# MSP432P411V register map
Vendor: Texas Instruments; File version: 3.230
CPU: 
Registers are 32-bit, read-write, reset 0x0 unless marked. A register's access mark holds for its fields unless they carry their own. Offsets are from the block's base; [hi:lo] are bit positions; {n}, {i} and the like mark numbered series; 'fields as' and 'values as' point back to an identical list.

## FLCTL_A
Base 0x40011000
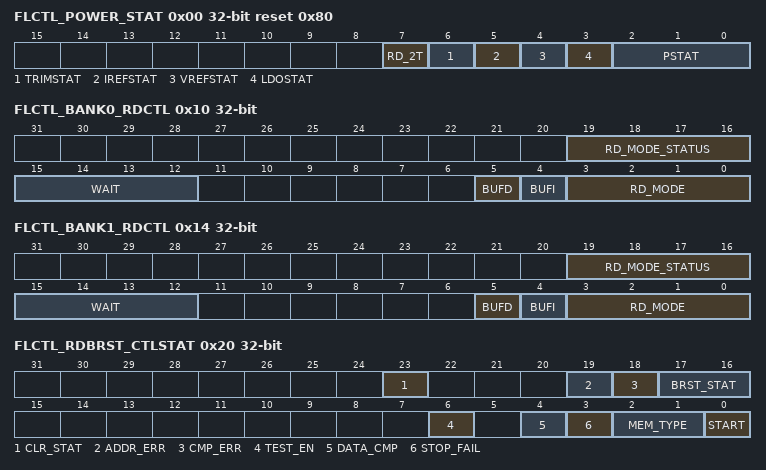
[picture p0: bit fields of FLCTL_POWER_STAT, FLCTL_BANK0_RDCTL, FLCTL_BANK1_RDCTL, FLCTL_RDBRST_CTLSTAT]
0x00 FLCTL_POWER_STAT ro reset 0x80 — Power Status Register
  [7] RD_2T — Indicates if Flash is being accessed in 2T mode
    0=Flash reads are in 1T mode; 1=Flash reads are in 2T mode
  [6] TRIMSTAT — PSS trim done status
    0=PSS trim not complete; 1=PSS trim complete
  [5] IREFSTAT — PSS IREF stable status
    0=IREF not stable; 1=IREF stable
  [4] VREFSTAT — PSS VREF stable status
    0=Flash LDO not stable; 1=Flash LDO stable
  [3] LDOSTAT — PSS FLDO GOOD status
    0=FLDO not GOOD; 1=FLDO GOOD
  [2:0] PSTAT — Flash power status
    0=Flash IP in power-down mode; 1=Flash IP Vdd domain power-up in progress; 2=PSS LDO_GOOD, IREF_OK and VREF_OK check in progress; 3=Flash IP SAFE_LV check in progress; 4=Flash IP Active; 5=Flash IP Active in Low-Frequency Active and Low-Frequency LPM0 modes; 6=Flash IP in Standby mode; 7=Flash IP in Current mirror boost state
0x10 FLCTL_BANK0_RDCTL access per field — Bank0 Read Control Register
  [19:16] RD_MODE_STATUS ro — Read mode
    0=Normal read mode; 1=Read Margin 0; 2=Read Margin 1; 3=Program Verify; 4=Erase Verify; 5=Leakage Verify; 9=Read Margin 0B; 10=Read Margin 1B
  [15:12] WAIT rw — Number of wait states for read
    {v}={v} wait states (v=0..15)
  [5] BUFD rw — Enables read buffering feature for data reads to this Bank
  [4] BUFI rw — Enables read buffering feature for instruction fetches to this Bank
  [3:0] RD_MODE rw — Flash read mode control setting for Bank 0
    values as RD_MODE_STATUS
0x14 FLCTL_BANK1_RDCTL access per field — Bank1 Read Control Register
  fields as FLCTL_BANK0_RDCTL
0x20 FLCTL_RDBRST_CTLSTAT access per field — Read Burst/Compare Control and Status Register
  [23] CLR_STAT wo — Clear status bits 19-16 of this register
  [19] ADDR_ERR ro — Burst/Compare Operation was terminated due to access to
  [18] CMP_ERR ro — Burst/Compare Operation encountered atleast one data
  [17:16] BRST_STAT ro — Status of Burst/Compare operation
    0=Idle; 1=Burst/Compare START bit written, but operation pending; 2=Burst/Compare in progress; 3=Burst complete (status of completed burst remains in this state unless explicitly cleared by SW)
  [6] TEST_EN rw — Enable comparison against test data compare registers
  [4] DATA_CMP rw — Data pattern used for comparison against memory read data
    0=0000_0000_0000_0000_0000_0000_0000_0000; 1=FFFF_FFFF_FFFF_FFFF_FFFF_FFFF_FFFF_FFFF
  [3] STOP_FAIL rw — Terminate burst/compare operation
  [2:1] MEM_TYPE rw — Type of memory that burst is carried out on
    0=Main Memory; 1=Information Memory; 3=Engineering Memory
  [0] START wo — Start of burst/compare operation
0x24 FLCTL_RDBRST_STARTADDR — Read Burst/Compare Start Address Register
  [20:0] START_ADDRESS — Start Address of Burst Operation
0x28 FLCTL_RDBRST_LEN — Read Burst/Compare Length Register
  [20:0] BURST_LENGTH — Length of Burst Operation
0x3C FLCTL_RDBRST_FAILADDR — Read Burst/Compare Fail Address Register
  [20:0] FAIL_ADDRESS — Reflects address of last failed compare
0x40 FLCTL_RDBRST_FAILCNT — Read Burst/Compare Fail Count Register
  [16:0] FAIL_COUNT — Number of failures encountered in burst operation
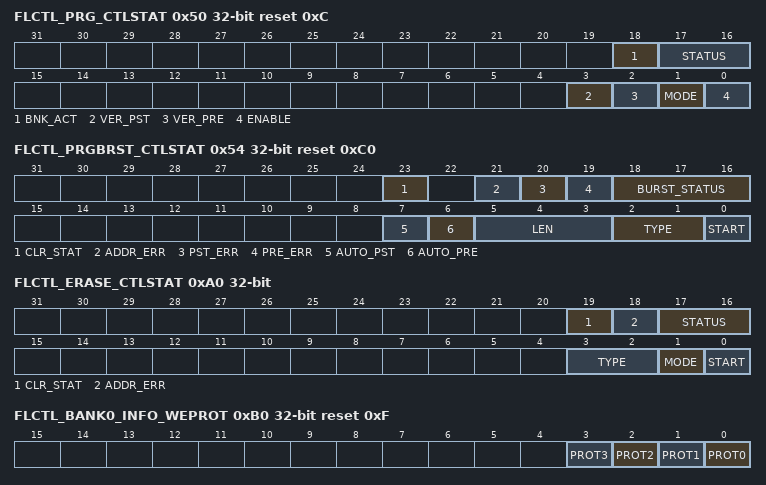
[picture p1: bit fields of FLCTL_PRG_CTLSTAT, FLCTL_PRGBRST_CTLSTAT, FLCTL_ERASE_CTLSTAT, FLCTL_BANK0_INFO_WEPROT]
0x50 FLCTL_PRG_CTLSTAT access per field reset 0xC — Program Control and Status Register
  [18] BNK_ACT ro — Bank active
    0=Word in Bank0 being programmed; 1=Word in Bank1 being programmed
  [17:16] STATUS ro — Status of program operations in the Flash memory
    0=Idle (no program operation currently active); 1=Single word program operation triggered, but pending; 2=Single word program in progress
  [3] VER_PST rw — Controls automatic post program verify operations
    0=No post program verification; 1=Post verify feature automatically invoked for each write operation (irrespective of the mode)
  [2] VER_PRE rw — Controls automatic pre program verify operations
    0=No pre program verification; 1=Pre verify feature automatically invoked for each write operation (irrespective of the mode)
  [1] MODE rw — Write mode
    0=Write immediate mode. Starts program operation immediately on each write to the Flash; 1=Full word write mode. Flash controller collates data over multiple writes to compose the full 128bit word before initiating the program operation
  [0] ENABLE rw — Master control for all word program operations
    0=Word program operation disabled; 1=Word program operation enabled
0x54 FLCTL_PRGBRST_CTLSTAT access per field reset 0xC0 — Program Burst Control and Status Register
  [23] CLR_STAT wo — Clear status bits 21-16 of this register
  [21] ADDR_ERR ro — Burst Operation was terminated due to attempted program of reserved memory
  [20] PST_ERR ro — Burst Operation encountered postprogram auto-verify errors
  [19] PRE_ERR ro — Burst Operation encountered preprogram auto-verify errors
  [18:16] BURST_STATUS ro — Status of a Burst Operation
    0=Idle (Burst not active); 1=Burst program started but pending; 2=Burst active, with 1st 128 bit word being written into Flash; 3=Burst active, with 2nd 128 bit word being written into Flash; 4=Burst active, with 3rd 128 bit word being written into Flash; 5=Burst active, with 4th 128 bit word being written into Flash; 7=Burst Complete (status of completed burst remains in this state unless explicitly cleared by SW)
  [7] AUTO_PST rw — Auto-Verify operation after the Burst Program
    0=No program verify operations carried out; 1=Causes an automatic Burst Program Verify before the Burst Program Operation
  [6] AUTO_PRE rw — Auto-Verify operation before the Burst Program
    0=No program verify operations carried out; 1=Causes an automatic Burst Program Verify after the Burst Program Operation
  [5:3] LEN rw — Length of burst
    0=No burst operation; 1=1 word burst of 128 bits, starting with address in the FLCTL_PRGBRST_STARTADDR Register; 2=2*128 bits burst write, starting with address in the FLCTL_PRGBRST_STARTADDR Register; 3=3*128 bits burst write, starting with address in the FLCTL_PRGBRST_STARTADDR Register; 4=4*128 bits burst write, starting with address in the FLCTL_PRGBRST_STARTADDR Register
  [2:1] TYPE rw — Type of memory that burst program is carried out on
    0=Main Memory; 1=Information Memory; 3=Engineering Memory
  [0] START wo — Trigger start of burst program operation
0x58 FLCTL_PRGBRST_STARTADDR — Program Burst Start Address Register
  [21:0] START_ADDRESS — Start Address of Program Burst Operation
{0x60+0x10*i} FLCTL_PRGBRST_DATA{i}_0 reset 0xFFFFFFFF (i=0..3) — Program Burst Data{i} Register0
  [31:0] DATAIN — Program Burst 128 bit Data Word {i}
{0x64+0x10*i} FLCTL_PRGBRST_DATA{i}_1 reset 0xFFFFFFFF (i=0..3) — Program Burst Data{i} Register1
  [31:0] DATAIN — Program Burst 128 bit Data Word {i}
{0x68+0x10*i} FLCTL_PRGBRST_DATA{i}_2 reset 0xFFFFFFFF (i=0..3) — Program Burst Data{i} Register2
  [31:0] DATAIN — Program Burst 128 bit Data Word {i}
{0x6C+0x10*i} FLCTL_PRGBRST_DATA{i}_3 reset 0xFFFFFFFF (i=0..3) — Program Burst Data{i} Register3
  [31:0] DATAIN — Program Burst 128 bit Data Word {i}
0xA0 FLCTL_ERASE_CTLSTAT access per field — Erase Control and Status Register
  [19] CLR_STAT wo — Clear status bits 18-16 of this register
  [18] ADDR_ERR ro — Erase Operation was terminated due to attempted erase of reserved memory address
  [17:16] STATUS ro — Status of erase operations in the Flash memory
    0=Idle (no program operation currently active); 1=Erase operation triggered to START but pending; 2=Erase operation in progress; 3=Erase operation completed (status of completed erase remains in this state unless explicitly cleared by SW)
  [3:2] TYPE rw — Type of memory that erase operation is carried out on
    0=Main Memory; 1=Information Memory; 3=Engineering Memory
  [1] MODE rw — Erase mode selected by application
    0=Sector Erase (controlled by FLTCTL_ERASE_SECTADDR); 1=Mass Erase (includes all Main and Information memory sectors that don't have corresponding WE bits set)
  [0] START wo — Start of Erase operation
0xA4 FLCTL_ERASE_SECTADDR — Erase Sector Address Register
  [21:0] SECT_ADDRESS — Address of Sector being Erased
0xB0 FLCTL_BANK0_INFO_WEPROT reset 0xF — Information Memory Bank0 Write/Erase Protection Register
  [n] PROT{n} (n=0..3) — Protects Sector {n} from program or erase
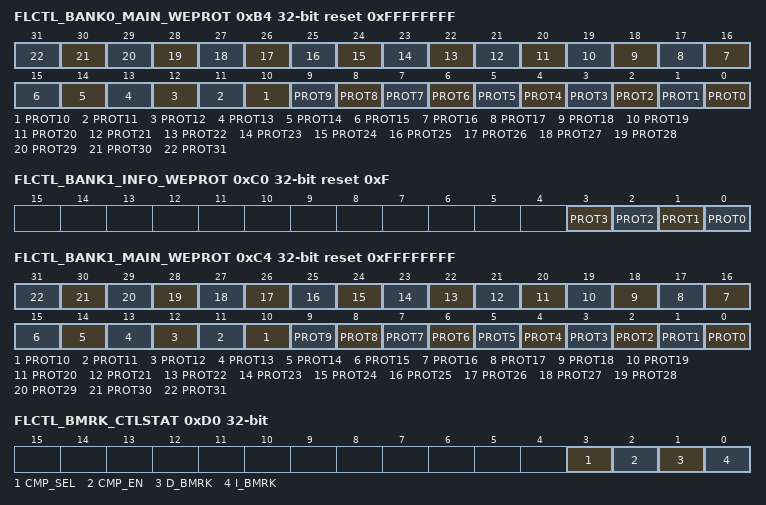
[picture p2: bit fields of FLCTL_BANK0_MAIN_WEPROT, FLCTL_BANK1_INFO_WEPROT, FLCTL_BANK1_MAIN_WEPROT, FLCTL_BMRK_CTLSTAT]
0xB4 FLCTL_BANK0_MAIN_WEPROT reset 0xFFFFFFFF — Main Memory Bank0 Write/Erase Protection Register
  [n] PROT{n} (n=0..31) — Protects Sector {n} from program or erase
0xC0 FLCTL_BANK1_INFO_WEPROT reset 0xF — Information Memory Bank1 Write/Erase Protection Register
  [3] PROT3 — Protects Sector 3 from program or erase
  [2] PROT2 — Protects Sector 2 from program or erase
  [1] PROT1 — Protects Sector 1 from program or erase operations
  [0] PROT0 — Protects Sector 0 from program or erase operations
0xC4 FLCTL_BANK1_MAIN_WEPROT reset 0xFFFFFFFF — Main Memory Bank1 Write/Erase Protection Register
  [n] PROT{n} (n=0..31) — Protects Sector {n} from program or erase operations
0xD0 FLCTL_BMRK_CTLSTAT — Benchmark Control and Status Register
  [3] CMP_SEL — Selects which benchmark register should be compared against the threshold
    0=en_1_0x0 (Compares the Instruction Benchmark Register against the threshold value); 1=en_2_0x1 (Compares the Data Benchmark Register against the threshold value)
  [2] CMP_EN — When 1, enables comparison of the Instruction or Data Benchmark Registers against the threshold value
  [1] D_BMRK — When 1, increments the Data Benchmark count register on each data read access to the Flash
  [0] I_BMRK — When 1, increments the Instruction Benchmark count register on each instruction fetch to the Flash
0xD4 FLCTL_BMRK_IFETCH — Benchmark Instruction Fetch Count Register
  [31:0] COUNT — Reflects the number of Instruction Fetches to the Flash (increments by one on each fetch)
0xD8 FLCTL_BMRK_DREAD — Benchmark Data Read Count Register
  [31:0] COUNT — Reflects the number of Data Read operations to the Flash (increments by one on each read)
0xDC FLCTL_BMRK_CMP reset 0x10000 — Benchmark Count Compare Register
  [31:0] COUNT — Reflects the threshold value that is compared against either the IFETCH or DREAD Benchmark Counters
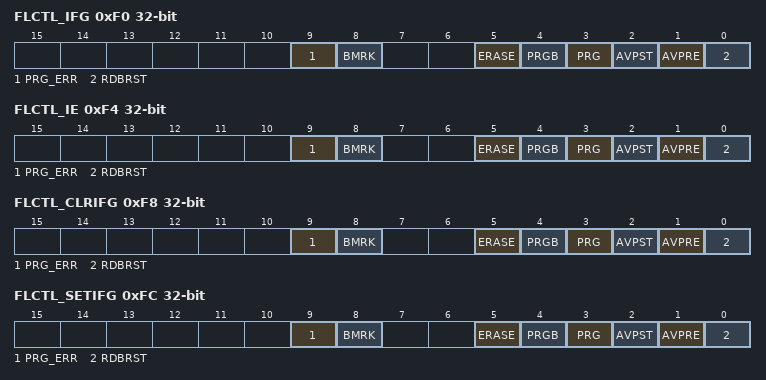
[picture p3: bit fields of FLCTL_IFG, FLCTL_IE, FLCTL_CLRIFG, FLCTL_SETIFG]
0xF0 FLCTL_IFG ro — Interrupt Flag Register
  [9] PRG_ERR — If set to 1, indicates a word composition error in full word write mode (possible data loss due to writes crossing over to a new 128bit boundary before full word has been composed)
  [8] BMRK — If set to 1, indicates that a Benchmark Compare match occurred
  [5] ERASE — If set to 1, indicates that the Erase operation is complete
  [4] PRGB — If set to 1, indicates that the configured Burst Program operation is complete
  [3] PRG — If set to 1, indicates that a word Program operation is complete
  [2] AVPST — If set to 1, indicates that the post-program verify operation has failed comparison
  [1] AVPRE — If set to 1, indicates that the pre-program verify operation has detected an error
  [0] RDBRST — If set to 1, indicates that the Read Burst/Compare operation is complete
0xF4 FLCTL_IE — Interrupt Enable Register
  [9] PRG_ERR — If set to 1, enables the Controller to generate an interrupt based on the corresponding bit in the FLCTL_IFG
  [8] BMRK — If set to 1, enables the Controller to generate an interrupt based on the corresponding bit in the FLCTL_IFG
  [5] ERASE — If set to 1, enables the Controller to generate an interrupt based on the corresponding bit in the FLCTL_IFG
  [4] PRGB — If set to 1, enables the Controller to generate an interrupt based on the corresponding bit in the FLCTL_IFG
  [3] PRG — If set to 1, enables the Controller to generate an interrupt based on the corresponding bit in the FLCTL_IFG
  [2] AVPST — If set to 1, enables the Controller to generate an interrupt based on the corresponding bit in the FLCTL_IFG
  [1] AVPRE — If set to 1, enables the Controller to generate an interrupt based on the corresponding bit in the FLCTL_IFG
  [0] RDBRST — If set to 1, enables the Controller to generate an interrupt based on the corresponding bit in the FLCTL_IFG
0xF8 FLCTL_CLRIFG wo — Clear Interrupt Flag Register
  [9] PRG_ERR — Write 1 clears the corresponding interrupt flag bit in the FLCTL_IFG
  [8] BMRK — Write 1 clears the corresponding interrupt flag bit in the FLCTL_IFG
  [5] ERASE — Write 1 clears the corresponding interrupt flag bit in the FLCTL_IFG
  [4] PRGB — Write 1 clears the corresponding interrupt flag bit in the FLCTL_IFG
  [3] PRG — Write 1 clears the corresponding interrupt flag bit in the FLCTL_IFG
  [2] AVPST — Write 1 clears the corresponding interrupt flag bit in the FLCTL_IFG
  [1] AVPRE — Write 1 clears the corresponding interrupt flag bit in the FLCTL_IFG
  [0] RDBRST — Write 1 clears the corresponding interrupt flag bit in the FLCTL_IFG
0xFC FLCTL_SETIFG wo — Set Interrupt Flag Register
  fields as FLCTL_CLRIFG
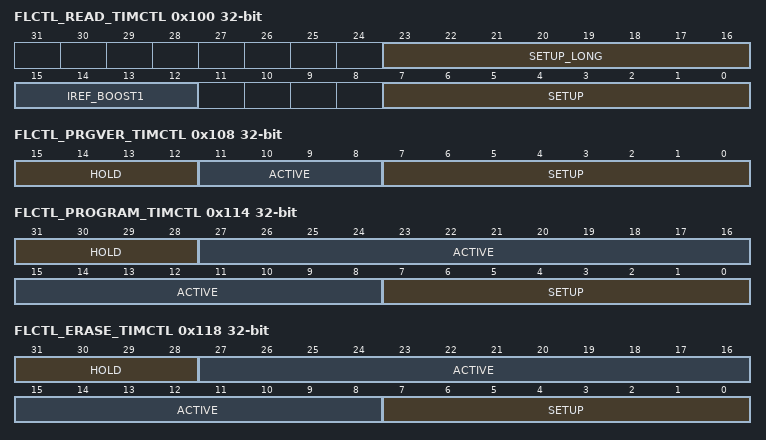
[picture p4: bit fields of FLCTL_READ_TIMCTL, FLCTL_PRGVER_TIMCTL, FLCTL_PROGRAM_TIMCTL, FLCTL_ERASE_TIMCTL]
0x100 FLCTL_READ_TIMCTL ro reset not defined — Read Timing Control Register
  [23:16] SETUP_LONG — Length of the Setup time into read mode when the device is recovering from one of the following conditions: Moving from Power-down or Standby back to Active and device is not trimmed. Moving from standby to active state in low-frequency active mode. Recovering from the LDO Boost operation after a Mass Erase.
  [15:12] IREF_BOOST1 — Length of the IREF_BOOST1 signal of the IP
  [7:0] SETUP — Configures the length of the Setup phase for this operation
0x104 FLCTL_READMARGIN_TIMCTL ro reset not defined — Read Margin Timing Control Register
  [7:0] SETUP — Length of the Setup phase for this operation
0x108 FLCTL_PRGVER_TIMCTL ro reset not defined — Program Verify Timing Control Register
  [15:12] HOLD — Length of the Hold phase for this operation
  [11:8] ACTIVE — Length of the Active phase for this operation
  [7:0] SETUP — Length of the Setup phase for this operation
0x10C FLCTL_ERSVER_TIMCTL ro reset not defined — Erase Verify Timing Control Register
  [7:0] SETUP — Length of the Setup phase for this operation
0x110 FLCTL_LKGVER_TIMCTL ro reset not defined — Leakage Verify Timing Control Register
  [7:0] SETUP — Length of the Setup phase for this operation
0x114 FLCTL_PROGRAM_TIMCTL ro reset not defined — Program Timing Control Register
  [31:28] HOLD — Length of the Hold phase for this operation
  [27:8] ACTIVE — Length of the Active phase for this operation
  [7:0] SETUP — Length of the Setup phase for this operation
0x118 FLCTL_ERASE_TIMCTL ro reset not defined — Erase Timing Control Register
  fields as FLCTL_PROGRAM_TIMCTL
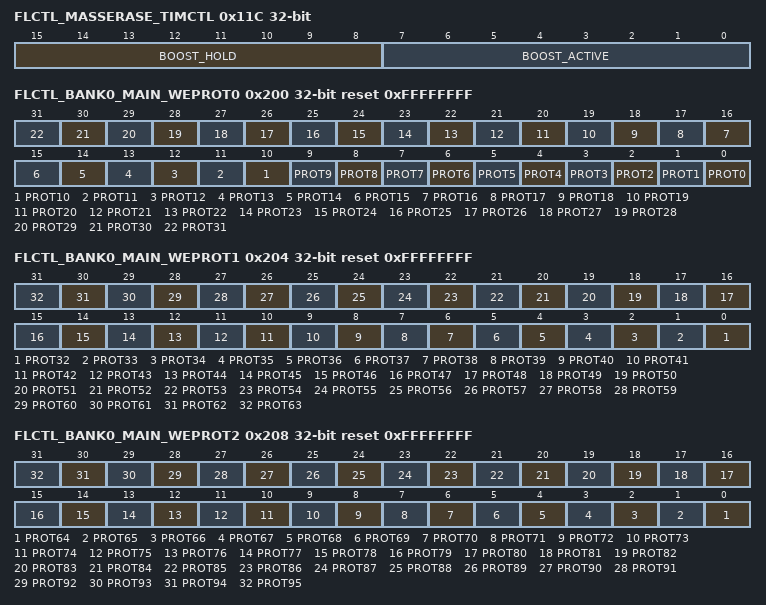
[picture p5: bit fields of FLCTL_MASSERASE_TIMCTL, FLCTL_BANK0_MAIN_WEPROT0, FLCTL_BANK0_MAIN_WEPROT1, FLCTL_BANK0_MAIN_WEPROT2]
0x11C FLCTL_MASSERASE_TIMCTL ro reset not defined — Mass Erase Timing Control Register
  [15:8] BOOST_HOLD — Length for which Flash deactivates the LDO Boost signal before processing any new commands
  [7:0] BOOST_ACTIVE — Length of the time for which LDO Boost Signal is kept active
0x120 FLCTL_BURSTPRG_TIMCTL ro reset not defined — Burst Program Timing Control Register
  [27:8] ACTIVE — Length of the Active phase for this operation
0x200 FLCTL_BANK0_MAIN_WEPROT0 reset 0xFFFFFFFF — Main Memory Bank0 Write/Erase Protection Register 0
  [n] PROT{n} (n=0..31) — Protects Sector {n} from program or erase
0x204 FLCTL_BANK0_MAIN_WEPROT1 reset 0xFFFFFFFF — Main Memory Bank0 Write/Erase Protection Register 1
  [n-32] PROT{n} (n=32..63) — Protects Sector {n} from program or erase
0x208 FLCTL_BANK0_MAIN_WEPROT2 reset 0xFFFFFFFF — Main Memory Bank0 Write/Erase Protection Register 2
  [n-64] PROT{n} (n=64..95) — Protects Sector {n} from program or erase
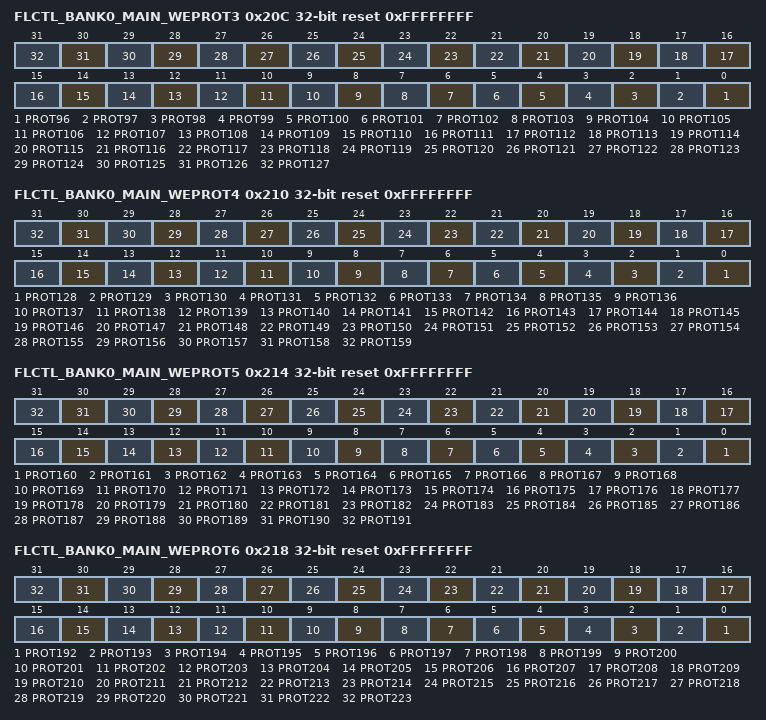
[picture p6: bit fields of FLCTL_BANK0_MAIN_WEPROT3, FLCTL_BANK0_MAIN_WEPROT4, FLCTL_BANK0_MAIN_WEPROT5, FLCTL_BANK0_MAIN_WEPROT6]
0x20C FLCTL_BANK0_MAIN_WEPROT3 reset 0xFFFFFFFF — Main Memory Bank0 Write/Erase Protection Register 3
  [n-96] PROT{n} (n=96..127) — Protects Sector {n} from program or erase
0x210 FLCTL_BANK0_MAIN_WEPROT4 reset 0xFFFFFFFF — Main Memory Bank0 Write/Erase Protection Register 4
  [n-128] PROT{n} (n=128..159) — Protects Sector {n} from program or erase
0x214 FLCTL_BANK0_MAIN_WEPROT5 reset 0xFFFFFFFF — Main Memory Bank0 Write/Erase Protection Register 5
  [n-160] PROT{n} (n=160..191) — Protects Sector {n} from program or erase
0x218 FLCTL_BANK0_MAIN_WEPROT6 reset 0xFFFFFFFF — Main Memory Bank0 Write/Erase Protection Register 6
  [n-192] PROT{n} (n=192..223) — Protects Sector {n} from program or erase
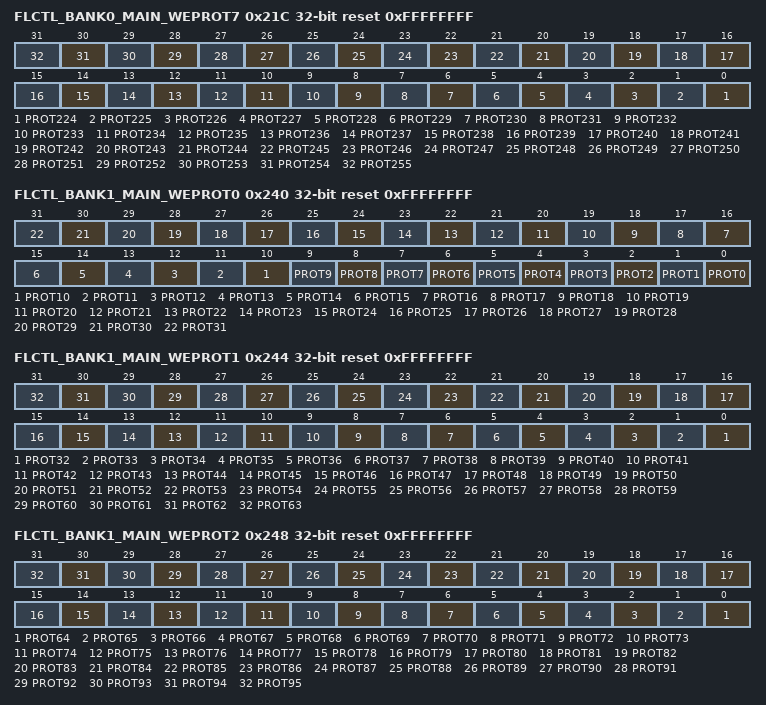
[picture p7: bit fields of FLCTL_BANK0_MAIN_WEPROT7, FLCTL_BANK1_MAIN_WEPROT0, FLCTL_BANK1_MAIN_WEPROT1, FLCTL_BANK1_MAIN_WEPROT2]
0x21C FLCTL_BANK0_MAIN_WEPROT7 reset 0xFFFFFFFF — Main Memory Bank0 Write/Erase Protection Register 7
  [n-224] PROT{n} (n=224..255) — Protects Sector {n} from program or erase
0x240 FLCTL_BANK1_MAIN_WEPROT0 reset 0xFFFFFFFF — Main Memory Bank1 Write/Erase Protection Register 0
  [n] PROT{n} (n=0..31) — Protects Sector {n} from program or erase
0x244 FLCTL_BANK1_MAIN_WEPROT1 reset 0xFFFFFFFF — Main Memory Bank1 Write/Erase Protection Register 1
  fields as FLCTL_BANK0_MAIN_WEPROT1
0x248 FLCTL_BANK1_MAIN_WEPROT2 reset 0xFFFFFFFF — Main Memory Bank1 Write/Erase Protection Register 2
  fields as FLCTL_BANK0_MAIN_WEPROT2
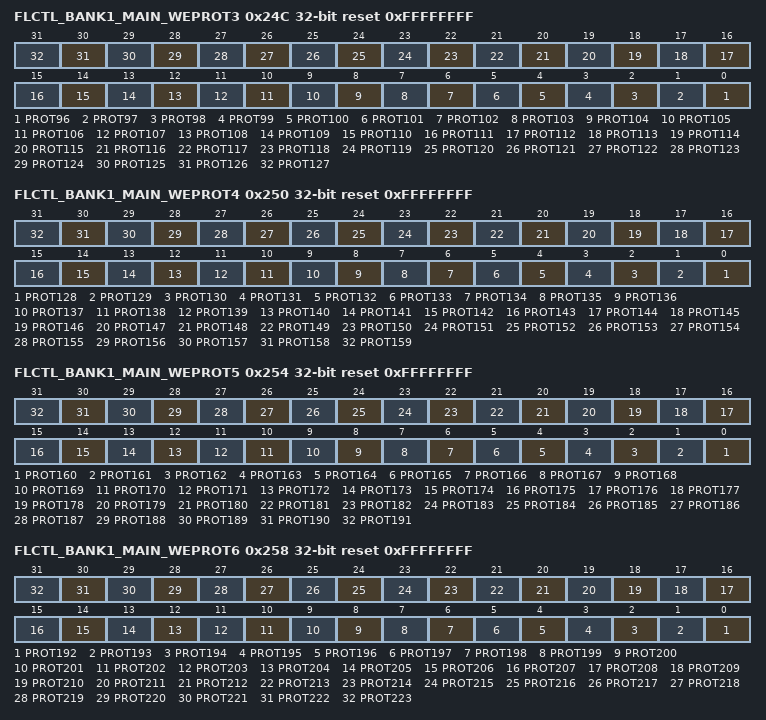
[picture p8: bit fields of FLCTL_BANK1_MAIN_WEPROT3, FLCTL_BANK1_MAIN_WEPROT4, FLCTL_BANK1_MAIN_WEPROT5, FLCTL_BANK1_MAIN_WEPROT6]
0x24C FLCTL_BANK1_MAIN_WEPROT3 reset 0xFFFFFFFF — Main Memory Bank1 Write/Erase Protection Register 3
  fields as FLCTL_BANK0_MAIN_WEPROT3
0x250 FLCTL_BANK1_MAIN_WEPROT4 reset 0xFFFFFFFF — Main Memory Bank1 Write/Erase Protection Register 4
  fields as FLCTL_BANK0_MAIN_WEPROT4
0x254 FLCTL_BANK1_MAIN_WEPROT5 reset 0xFFFFFFFF — Main Memory Bank1 Write/Erase Protection Register 5
  fields as FLCTL_BANK0_MAIN_WEPROT5
0x258 FLCTL_BANK1_MAIN_WEPROT6 reset 0xFFFFFFFF — Main Memory Bank1 Write/Erase Protection Register 6
  fields as FLCTL_BANK0_MAIN_WEPROT6
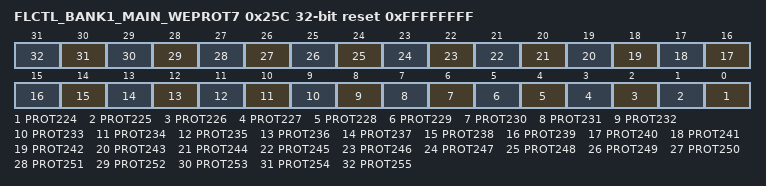
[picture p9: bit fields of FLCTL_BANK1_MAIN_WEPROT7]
0x25C FLCTL_BANK1_MAIN_WEPROT7 reset 0xFFFFFFFF — Main Memory Bank1 Write/Erase Protection Register 7
  fields as FLCTL_BANK0_MAIN_WEPROT7
